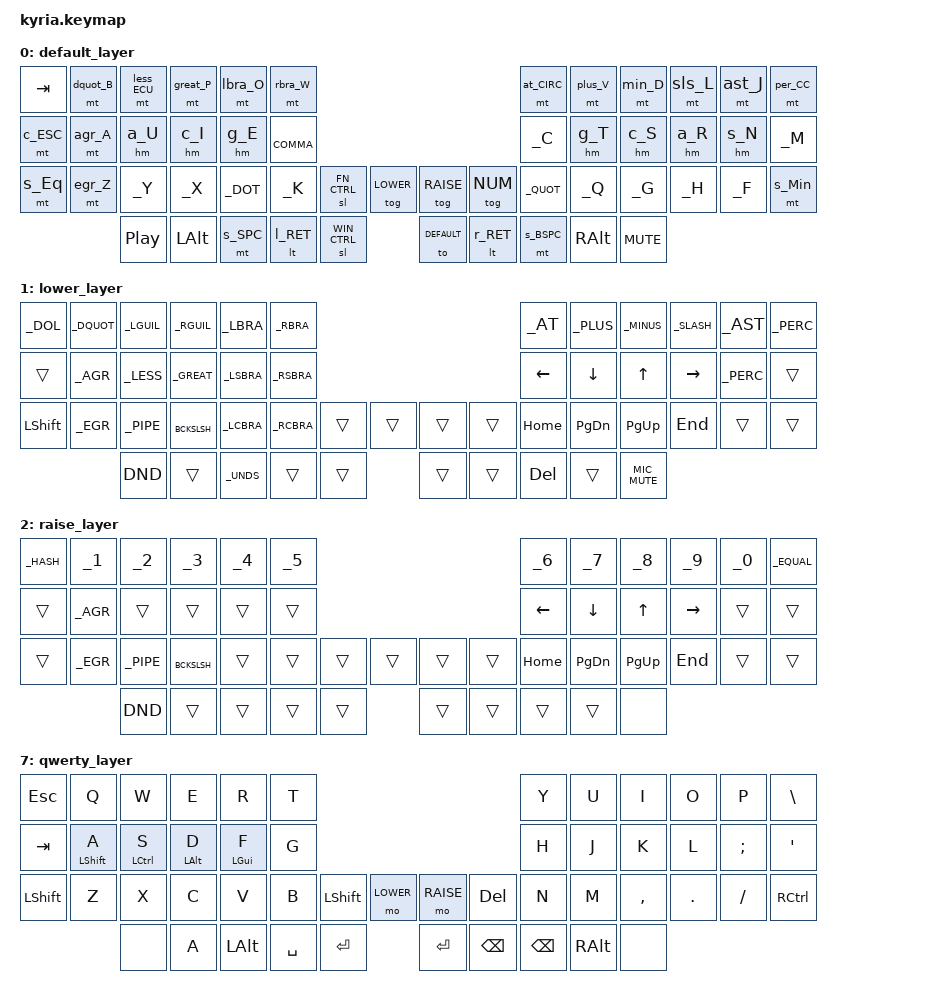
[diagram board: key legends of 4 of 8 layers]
/*
 * Copyright (c) 2020 The ZMK Contributors
 *
 * SPDX-License-Identifier: MIT
 */

#include <behaviors.dtsi>
#include <dt-bindings/zmk/keys.h>
#include <dt-bindings/zmk/bt.h>

#include "bepo-keymap.h"

#define QUICK_TAP_TIMEOUT 300
#define STICKY_TIMEOUT 5000

// Encoder resolutions
&left_encoder   { resolution = <2>; };
&right_encoder  { resolution = <8>; };

// layers
#define DEFAULT   0
#define LOWER     1
#define RAISE     2
#define WIN_CTRL  3
#define FN_CTRL   4
#define NUM       5
#define BLUETOOTH 6
#define QWERTY    7


// None/Trans
#define _____ &none
#define t____ &trans

#define c_ESC LCTRL ESC

#define s_Eq LSHFT _EQUAL
#define s_Min RSHFT _MINUS
#define s_A LSHFT _A
#define a_U LALT _U
#define c_I LCTRL _I
#define g_E LGUI _E
#define s_N RSHFT _N
#define a_R RALT _R
#define c_S RCTRL _S
#define g_T RGUI _T
#define s_SPC LSHFT SPC
#define l_RET LOWER RET
#define r_RET RAISE RET
#define s_BSPC RSHFT BSPC

#define dquot_B _DQUOT _B
#define less_ECU _LESS _ECU
#define great_P _GREAT _P
#define lbra_O _LBRA _O
#define rbra_W _RBRA _W

// long press behavior
#define at_CIRC _AT _CIRC
#define plus_V _PLUS _V
#define min_D _MINUS _D
#define sls_L _SLASH _L
#define ast_J _AST _J
#define per_CC _PERC _CCED
#define agr_A _AGR _A
#define egr_Z _EGR _Z
#define C_MIC_MUTE RG(RC(LA(RS(_M))))
#define C_DND LC(LA(LS(_N)))

&mt {
  flavor = "tap-preferred";
  quick-tap-ms = <QUICK_TAP_TIMEOUT>;
};

&sl { release-after-ms = <STICKY_TIMEOUT>; };

/ {
    combos {
      compatible = "zmk,combos";
        combo_esc {
          timeout-ms = <50>;
          key-positions = <0 11>;
          bindings = <&to DEFAULT>;
      };
        combo_ctrl_alt {
          timeout-ms = <75>;
          key-positions = <14 15>;
          bindings = <&sk LC(LALT)>;
          layers = <FN_CTRL>;
      };
        combo_shift {
          timeout-ms = <75>;
          key-positions = <15 16>;
          bindings = <&sk LSHFT>;
          layers = <FN_CTRL>;
      };
        combo_to_bluetooth {
          timeout-ms = <75>;
          key-positions = <44 45>;
          bindings = <&sl BLUETOOTH>;
      };
        combo_to_bluetooth_alt {
          timeout-ms = <75>;
          key-positions = <0 12>;
          bindings = <&sl BLUETOOTH>;
      };
    };

    behaviors {
        hm: homerow_mods {
            compatible = "zmk,behavior-hold-tap";
            label = "HOMEROW_MODS";
            #binding-cells = <2>;
            tapping-term-ms = <300>;
            quick-tap-ms = <QUICK_TAP_TIMEOUT>;
            flavor = "tap-preferred";
            bindings = <&kp>, <&kp>;
        };
    };

	keymap {
		compatible = "zmk,keymap";

		default_layer {
// ---------------------------------------------------------------------------------------------------------------------------------
// |  TAB  |  B  |  É  |  P   |  O   |  W    |                                          |  ^   |  V    |  D    |  L   |   J   |   Ç  |
// |  ESC  |  A  |  U  |  I   |  E   |  ,    |                                          |  C   |  T    |  S    |  R   |   N   |   M  |
// |SHIFT·=|  Z  |  Y  |  X   |  .   |  K    | FN_CTRL |  LOWER  |  |  RAISE  |   DEL   |  '   |  Q    |  G    |  H   |   F   |   =  |
//                     |  ⮾   | L-ALT | S·SPC | R·RET | WIN_CTRL |  |   RET   |   RET  | BSPC | R-ALT |   ⮾   |
			bindings = <
	&kp TAB   &mt dquot_B &mt less_ECU &mt great_P &mt lbra_O &mt rbra_W                                              &mt at_CIRC &mt plus_V &mt min_D &mt sls_L &mt ast_J &mt per_CC
	&mt c_ESC &mt agr_A   &hm a_U      &hm c_I     &hm g_E    &kp _COMMA                                              &kp _C      &hm g_T    &hm c_S   &hm a_R   &hm s_N   &kp _M
	&mt s_Eq  &mt egr_Z   &kp _Y       &kp _X      &kp _DOT   &kp _K &sl FN_CTRL &tog LOWER      &tog RAISE  &tog NUM &kp _QUOT   &kp _Q     &kp _G    &kp _H    &kp _F    &mt s_Min
                                &kp C_PP &kp LALT    &mt s_SPC       &lt l_RET   &sl WIN_CTRL    &to DEFAULT &lt r_RET  &mt s_BSPC &kp RALT &kp C_MUTE
			>;

            sensor-bindings = <&inc_dec_kp C_VOL_DN C_VOL_UP &inc_dec_kp DOWN UP>;
		};


		lower_layer {
// ---------------------------------------------------------------------------------------------------------------------------------
// |   $   |  "  |  «  |  »   |  (   |  )    |                                          |  @   |  +    |  -    |  /   |   *   |   %  |
// |  TAB  |  à  |  <  |  >   |  [   |  ]    |                                          | LEFT | DOWN  |  UP   | RIGHT|   %   |      |
// | SHIFT |  è  |  Y  |  X   |  {   |  }    | L SHIFT | L SHIFT |  | L SHIFT |   DEL   |  '   |   Q   |   G   |   H  |   F   | CTRL |
//                     |  ⮾   | GUI  | L-ALT |   SPC   |   RET   |  |   RET   |   BSPC  | BSPC | R-ALT |   ⮾   |
			bindings = <
	&kp _DOL  &kp _DQUOT &kp _LGUIL &kp _RGUIL   &kp _LBRA  &kp _RBRA                               &kp _AT  &kp _PLUS &kp _MINUS &kp _SLASH &kp _AST  &kp _PERC
	t____     &kp _AGR   &kp _LESS  &kp _GREAT   &kp _LSBRA &kp _RSBRA                              &kp LEFT &kp DOWN  &kp UP     &kp RIGHT  &kp _PERC t____
	&kp LSHFT &kp _EGR   &kp _PIPE  &kp _BCKSLSH &kp _LCBRA &kp _RCBRA t____  t____     t____ t____ &kp HOME &kp PG_DN &kp PG_UP  &kp END    t____     t____
	                                       &kp C_DND t____  &kp _UNDS  t____  t____     t____ t____ &kp DEL  t____   &kp C_MIC_MUTE
			>;

			sensor-bindings = <&inc_dec_kp C_PREV C_NEXT &inc_dec_kp PG_UP PG_DN>;
		};

		raise_layer {
// ---------------------------------------------------------------------------------------------------------------------------------
// |  ESC  |  1  |  2  |  3   |  4   |  5    |                                          |  6   |  7    |  8    |  9   |   0   |   \  |
// |  TAB  |  A  |  S  |  D   |  F   |  G    |                                          | LEFT | DOWN  |  UP   | RIGHT|       |      |
// | SHIFT |  Z  |  X  |  C   |  V   |  B    | L SHIFT | L SHIFT |  | L SHIFT |   DEL   |  N   |  M    |  ,    |  .   |   /   | CTRL |
//                     |  ⮾   | GUI  | L-ALT |   SPC   |   RET   |  |   RET   |   BSPC  | BSPC | R-ALT |   ⮾   |
			bindings = <
	&kp _HASH &kp _1       &kp _2      &kp _3       &kp _4      &kp _5                             &kp _6    &kp _7      &kp _8       &kp _9       &kp _0 &kp _EQUAL
	t____     &kp _AGR     t____       t____        t____       t____                              &kp LEFT  &kp DOWN    &kp UP       &kp RIGHT    t____      t____
	t____     &kp _EGR     &kp _PIPE   &kp _BCKSLSH t____       t____ t____  t____    t____ t____  &kp HOME  &kp PG_DN   &kp PG_UP    &kp END      t____      t____
	                                     &kp C_DND  t____   t____   t____   t____    t____   t____    t____   t____   &none
			>;

			sensor-bindings = <&inc_dec_kp LC(LS(TAB)) LC(TAB) &inc_dec_kp PG_UP PG_DN>;
		};

		win_ctrl_layer {
// ---------------------------------------------------------------------------------------------------------------------------------
// |  ESC  |  1  |  2  |  3   |  4   |  5    |                                          |  6   |  7    |  8    |  9   |   0   |   \  |
// |  TAB  |  A  |  S  |  D   |  F   |  G    |                                          | LEFT | DOWN  |  UP   | RIGHT|       |      |
// | SHIFT |  Z  |  X  |  C   |  V   |  B    | L SHIFT | L SHIFT |  | L SHIFT |   DEL   |  N   |  M    |  ,    |  .   |   /   | CTRL |
//                     |  ⮾   | GUI  | L-ALT |   SPC   |   RET   |  |   RET   |   BSPC  | BSPC | R-ALT |   ⮾   |
			bindings = <
	_____     &kp LG(_1)   &kp LG(_2) &kp LG(_3)     &kp LG(_4)  &kp LG(_5)              &kp _6    &kp _7      &kp _8       &kp _9       &kp _0 &kp _EQUAL
	_____     _____        _____      &kp LG(LC(_F)) &kp LG(_F)  _____                   &kp LEFT  &kp DOWN    &kp UP       &kp RIGHT    t____      t____
	_____     _____        _____      _____          _____       _____               t____     t____       t____        t____        t____      t____
	                                    &none   t____   t____   t____   t____    t____   t____   &kp DEL   t____   &none
			>;

			sensor-bindings = <&inc_dec_kp C_VOL_DN C_VOL_UP &inc_dec_kp PG_UP PG_DN>;
		};

	    fn_ctrl_layer {
// ---------------------------------------------------------------------------------------------------------------------------------
// |  ESC  | F1  | F2  | F3   | F4   | F5    |                                          |  6   |  7    |  8    |  9   |   0   |   \  |
// |  TAB  |SHIFT| ALT | CTRL |  GUI |  G    |                                          | LEFT | DOWN  |  UP   | RIGHT|       |      |
// | SHIFT |  Z  |  X  |  C   |  V   |  B    |    F11   |   F12   |  | L SHIFT |   DEL   |  N   |  M    |  ,    |  .   |   /   | CTRL |
//                     |  ⮾   | GUI  | L-ALT |   SPC   |   RET   |  |   RET   |   BSPC  | BSPC | R-ALT |   ⮾   |
			bindings = <
	&kp F12  &kp F1     &kp F2    &kp F3     &kp F4      &kp F5                               &kp F6    &kp F7      &kp F8       &kp F9       &kp F10    &kp F11
	_____    &sk LSHFT  &sk LALT  &sk LCTRL  &sk LGUI    t____                                t____     t____       t____        t____        t____      t____
	_____    t____      t____      t____     t____       t____                                t____     t____       t____        t____        t____      t____
	t____    t____      t____      t____     t____       t____  &kp F11 &kp F12  t____ t____  &kp HOME  &kp PG_DN   &kp PG_UP    &kp END      t____      t____
	                                     &none   t____   t____  t____   t____    t____ t____   &kp DEL   t____   &none
			>;

			sensor-bindings = <&inc_dec_kp C_VOL_DN C_VOL_UP &inc_dec_kp PG_UP PG_DN>;
		};

	    num_layer {
// ---------------------------------------------------------------------------------------------------------------------------------
// |  ESC  | F1  | F2  | F3   | F4   | F5    |                                          |  6   |  7    |  8    |  9   |   0   |   \  |
// |  TAB  |SHIFT| ALT | CTRL |  GUI |  G    |                                          | LEFT | DOWN  |  UP   | RIGHT|       |      |
// | SHIFT |  Z  |  X  |  C   |  V   |  B    |    F11   |   F12   |  | L SHIFT |   DEL   |  N   |  M    |  ,    |  .   |   /   | CTRL |
//                     |  ⮾   | GUI  | L-ALT |   SPC   |   RET   |  |   RET   |   BSPC  | BSPC | R-ALT |   ⮾   |
			bindings = <
	&kp F12  &kp F1     &kp F2    &kp F3     &kp F4      &kp F5                               &kp F6    &kp F7      &kp F8       &kp F9       &kp F10    &kp F11
	_____    &sk LSHFT  &sk LALT  &sk LCTRL  &sk LGUI    t____                                t____     &kp _7      &kp _8       &kp _9       t____      t____
	_____    t____      t____      t____     t____       t____                                t____     &kp _4      &kp _5       &kp _6       t____      t____
    t____    t____      t____      t____     t____       t____  &kp F11 &kp F12  t____ t____  t____     &kp _1      &kp _2       &kp _3       t____      t____
                                         &none   t____   t____  t____   t____    t____ t____  &kp _0    t____   &none
			>;

			sensor-bindings = <&inc_dec_kp C_VOL_DN C_VOL_UP &inc_dec_kp PG_UP PG_DN>;
		};

	    bluetooth_layer {
// ---------------------------------------------------------------------------------------------------------------------------------
// |  ESC  | F1  | F2  | F3   | F4   | F5    |                                          |  6   |  7    |  8    |  9   |   0   |   \  |
// |  TAB  |SHIFT| ALT | CTRL |  GUI |  G    |                                          | LEFT | DOWN  |  UP   | RIGHT|       |      |
// | SHIFT |  Z  |  X  |  C   |  V   |  B    | L SHIFT | L SHIFT |  | L SHIFT |   DEL   |  N   |  M    |  ,    |  .   |   /   | CTRL |
//                     |  ⮾   | GUI  | L-ALT |   SPC   |   RET   |  |   RET   |   BSPC  | BSPC | R-ALT |   ⮾   |
			bindings = <
	_____     &bt BT_SEL 0 &bt BT_SEL 1 &bt BT_SEL 2 &sk LGUI    _____               _____     _____       _____        _____        _____      _____
	&to DEFAULT _____    _____    _____    _____    _____       _____     _____       _____        _____        _____      _____
	_____     _____        _____       _____        _____       _____               _____     _____       _____        _____        _____      _____
	                                     _____   _____   _____   _____   _____    _____   _____   &bt BT_CLR   _____   _____
			>;

			sensor-bindings = <&inc_dec_kp C_VOL_DN C_VOL_UP &inc_dec_kp PG_UP PG_DN>;
		};

		qwerty_layer {
// ---------------------------------------------------------------------------------------------------------------------------------
// |  ESC  |  Q  |  W  |  E   |  R   |  T    |                                          |  Y   |  U    |  I    |  O   |   P   |   \  |
// |  TAB  |  A  |  S  |  D   |  F   |  G    |                                          |  H   |  J    |  K    |  L   |   ;   |   '  |
// | SHIFT |  Z  |  X  |  C   |  V   |  B    | L SHIFT | L SHIFT |  | L SHIFT |   DEL   |  N   |  M    |  ,    |  .   |   /   | CTRL |
//                     |  ⮾   | GUI  | L-ALT |   SPC   |   RET   |  |   RET   |   BSPC  | BSPC | R-ALT |   ⮾   |
			bindings = <
	&kp ESC   &kp Q       &kp W       &kp E      &kp R      &kp T                          &kp Y &kp U  &kp I     &kp O   &kp P    &kp BSLH
	&kp TAB   &hm LSHFT A &hm LCTRL S &hm LALT D &hm LGUI F &kp G                          &kp H &kp J  &kp K     &kp L   &kp SEMI &kp SQT
	&kp LSHFT &kp Z &kp X &kp C &kp V &kp B &kp LSHFT &mo LOWER        &mo RAISE &kp DEL   &kp N &kp M  &kp COMMA &kp DOT &kp FSLH &kp RCTRL
	                &none         &kp A &kp LALT &kp SPACE &kp RET     &kp RET   &kp BSPC  &kp BSPC &kp RALT &none
			>;

			sensor-bindings = <&inc_dec_kp C_VOL_DN C_VOL_UP &inc_dec_kp PG_UP PG_DN>;
		};
	};
};
